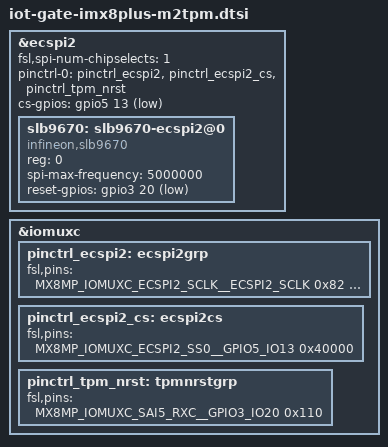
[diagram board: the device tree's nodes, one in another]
&ecspi2 {
	#address-cells = <1>;
	#size-cells = <0>;
	fsl,spi-num-chipselects = <1>;
	pinctrl-names = "default";
	pinctrl-0 = <&pinctrl_ecspi2>, <&pinctrl_ecspi2_cs>, <&pinctrl_tpm_nrst>;
	cs-gpios = <&gpio5 13 GPIO_ACTIVE_LOW>;
	status = "okay";

	slb9670: slb9670-ecspi2@0 {
		compatible = "infineon,slb9670", "tcg,tpm_tis-spi";
		reg = <0>;
		spi-max-frequency = <5000000>;
		reset-gpios = <&gpio3 20 GPIO_ACTIVE_LOW>;
		status = "okay";
	};
};

&iomuxc {
	pinctrl_ecspi2: ecspi2grp {
		fsl,pins = <
			MX8MP_IOMUXC_ECSPI2_SCLK__ECSPI2_SCLK				0x82
			MX8MP_IOMUXC_ECSPI2_MOSI__ECSPI2_MOSI				0x82
			MX8MP_IOMUXC_ECSPI2_MISO__ECSPI2_MISO				0x82
		>;
	};

	pinctrl_ecspi2_cs: ecspi2cs {
		fsl,pins = <
			MX8MP_IOMUXC_ECSPI2_SS0__GPIO5_IO13				0x40000
		>;
	};
	pinctrl_tpm_nrst: tpmnrstgrp {
		fsl,pins = <
			MX8MP_IOMUXC_SAI5_RXC__GPIO3_IO20			0x110
		>;
	};
};
